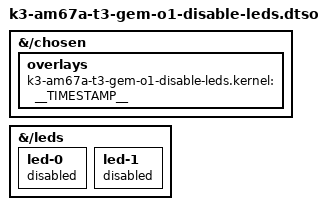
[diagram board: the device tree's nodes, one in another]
// SPDX-License-Identifier: GPL-2.0-only OR MIT
/*
 * DT Overlay for disabling on-board leds if you want to use them on your own.
 *
 * Copyright (C) 2023 Texas Instruments Incorporated - https://www.ti.com/
 *
 */

/dts-v1/;
/plugin/;

#include <dt-bindings/leds/common.h>
#include <dt-bindings/gpio/gpio.h>
#include "k3-pinctrl.h"

/*
 * Helper to show loaded overlays under: /proc/device-tree/chosen/overlays/
*/
&{/chosen} {
	overlays {
		k3-am67a-t3-gem-o1-disable-leds.kernel = __TIMESTAMP__;
	};
};

&{/leds} {
	led-0 {
		status = "disabled";
	};
	led-1 {
		status = "disabled";
	};
};
